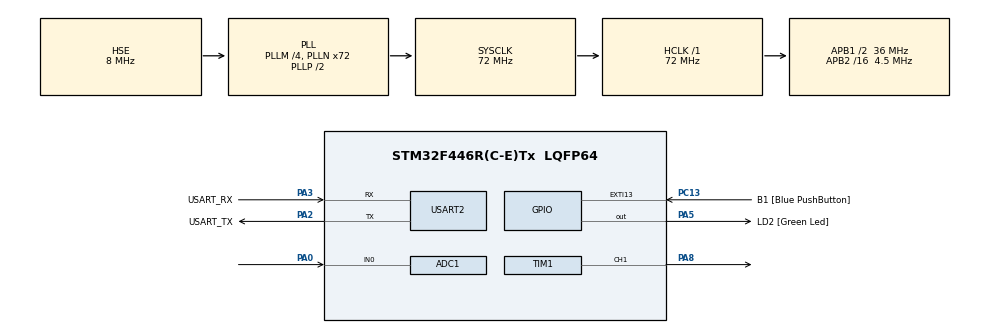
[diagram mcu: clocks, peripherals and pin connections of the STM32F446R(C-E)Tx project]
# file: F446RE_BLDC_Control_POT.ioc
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ADC1.Channel-0\#ChannelRegularConversion=ADC_CHANNEL_0
ADC1.ContinuousConvMode=ENABLE
ADC1.NbrOfConversionFlag=1
ADC1.Rank-0\#ChannelRegularConversion=1
ADC1.SamplingTime-0\#ChannelRegularConversion=ADC_SAMPLETIME_3CYCLES
ADC1.ScanConvMode=ENABLE
ADC1.master=1
Dma.ADC1.0.Direction=DMA_PERIPH_TO_MEMORY
Dma.ADC1.0.FIFOMode=DMA_FIFOMODE_DISABLE
Dma.ADC1.0.Instance=DMA2_Stream0
Dma.ADC1.0.MemDataAlignment=DMA_MDATAALIGN_HALFWORD
Dma.ADC1.0.MemInc=DMA_MINC_ENABLE
Dma.ADC1.0.Mode=DMA_CIRCULAR
Dma.ADC1.0.PeriphDataAlignment=DMA_PDATAALIGN_HALFWORD
Dma.ADC1.0.PeriphInc=DMA_PINC_DISABLE
Dma.ADC1.0.Priority=DMA_PRIORITY_LOW
Dma.Request0=ADC1
Mcu.Family=STM32F4
Mcu.Name=STM32F446R(C-E)Tx
Mcu.Package=LQFP64
NVIC.ADC_IRQn=true\:0\:0\:false\:false\:true\:true\:true\:true
NVIC.DMA2_Stream0_IRQn=true\:0\:0\:false\:false\:true\:false\:true\:true
NVIC.PriorityGroup=NVIC_PRIORITYGROUP_0
PA0-WKUP.Signal=ADCx_IN0
PA13.GPIO_Label=TMS
PA13.Mode=Serial_Wire
PA13.Signal=SYS_JTMS-SWDIO
PA14.GPIO_Label=TCK
PA14.Mode=Serial_Wire
PA14.Signal=SYS_JTCK-SWCLK
PA2.GPIO_Label=USART_TX
PA2.Mode=Asynchronous
PA2.Signal=USART2_TX
PA3.GPIO_Label=USART_RX
PA3.Mode=Asynchronous
PA3.Signal=USART2_RX
PA5.GPIO_Label=LD2 [Green Led]
PA5.Signal=GPIO_Output
PA8.Signal=S_TIM1_CH1
PB3.GPIO_Label=SWO
PB3.Signal=SYS_JTDO-SWO
PC13.GPIO_Label=B1 [Blue PushButton]
PC13.GPIO_ModeDefaultEXTI=GPIO_MODE_IT_FALLING
PC13.Signal=GPXTI13
PC14-OSC32_IN.Mode=LSE-External-Oscillator
PC14-OSC32_IN.Signal=RCC_OSC32_IN
PC15-OSC32_OUT.Mode=LSE-External-Oscillator
PC15-OSC32_OUT.Signal=RCC_OSC32_OUT
PH0-OSC_IN.Mode=HSE-External-Oscillator
PH0-OSC_IN.Signal=RCC_OSC_IN
PH1-OSC_OUT.Mode=HSE-External-Oscillator
PH1-OSC_OUT.Signal=RCC_OSC_OUT
ProjectManager.HeapSize=0x200
ProjectManager.StackSize=0x400
ProjectManager.TargetToolchain=STM32CubeIDE
RCC.48MHZClocksFreq_Value=84000000
RCC.AHBFreq_Value=72000000
RCC.APB1CLKDivider=RCC_HCLK_DIV2
RCC.APB1Freq_Value=36000000
RCC.APB1TimFreq_Value=72000000
RCC.APB2CLKDivider=RCC_HCLK_DIV16
RCC.APB2Freq_Value=4500000
RCC.APB2TimFreq_Value=9000000
RCC.CortexFreq_Value=72000000
RCC.FLatency-AdvancedSettings=FLASH_LATENCY_2
RCC.HCLKFreq_Value=72000000
RCC.HSE_VALUE=8000000
RCC.HSI_VALUE=16000000
RCC.PLLM=4
RCC.PLLN=72
RCC.PLLSourceVirtual=RCC_PLLSOURCE_HSE
RCC.SYSCLKFreq_VALUE=72000000
RCC.SYSCLKSource=RCC_SYSCLKSOURCE_PLLCLK
RCC.USBFreq_Value=72000000
RCC.VCOOutputFreq_Value=144000000
SH.ADCx_IN0.0=ADC1_IN0,IN0
SH.S_TIM1_CH1.0=TIM1_CH1,PWM Generation1 CH1
TIM1.Channel-PWM\ Generation1\ CH1=TIM_CHANNEL_1
TIM1.Period=1000-1
TIM1.Prescaler=180-1
USART2.VirtualMode=VM_ASYNC
VP_TIM1_VS_ClockSourceINT.Mode=Internal
board=NUCLEO-F446RE

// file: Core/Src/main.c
/* USER CODE BEGIN Header */
/**
  ******************************************************************************
  * @file           : main.c
  * @brief          : Main program body
  ******************************************************************************
  * @attention
  *
  * Copyright (c) 2024 STMicroelectronics.
  * All rights reserved.
  *
  * This software is licensed under terms that can be found in the LICENSE file
  * in the root directory of this software component.
  * If no LICENSE file comes with this software, it is provided AS-IS.
  *
  ******************************************************************************
  */
/* USER CODE END Header */
#include "main.h"

ADC_HandleTypeDef hadc1;
DMA_HandleTypeDef hdma_adc1;

TIM_HandleTypeDef htim1;

UART_HandleTypeDef huart2;

void SystemClock_Config(void);
static void MX_GPIO_Init(void);
static void MX_DMA_Init(void);
static void MX_USART2_UART_Init(void);
static void MX_TIM1_Init(void);
static void MX_ADC1_Init(void);

/* USER CODE BEGIN 0 */
uint16_t i = 0;
uint16_t adc_value = 0;
uint16_t ADc_Converted = 0;

long map(long x, long in_min, long in_max, long out_min, long out_max) {
  return (x - in_min) * (out_max - out_min) / (in_max - in_min) + out_min;
}

void HAL_ADC_ConvCpltCallback(ADC_HandleTypeDef* hadc)
{

}
/* USER CODE END 0 */

int main(void)
{

  /* MCU Configuration--------------------------------------------------------*/

  /* Reset of all peripherals, Initializes the Flash interface and the Systick. */
  HAL_Init();

  /* Configure the system clock */
  SystemClock_Config();

  /* Initialize all configured peripherals */
  MX_GPIO_Init();
  MX_DMA_Init();
  MX_USART2_UART_Init();
  MX_TIM1_Init();
  MX_ADC1_Init();
  /* USER CODE BEGIN 2 */
  HAL_TIM_PWM_Start(&htim1, TIM_CHANNEL_1);

  HAL_ADC_Start_DMA(&hadc1, (uint32_t *)&adc_value, 1);

  /* USER CODE END 2 */

  /* Infinite loop */
  while (1)
  {

  }
}

void SystemClock_Config(void)
{
  RCC_OscInitTypeDef RCC_OscInitStruct = {0};
  RCC_ClkInitTypeDef RCC_ClkInitStruct = {0};

  /** Configure the main internal regulator output voltage
  */
  __HAL_RCC_PWR_CLK_ENABLE();
  __HAL_PWR_VOLTAGESCALING_CONFIG(PWR_REGULATOR_VOLTAGE_SCALE3);

  /** Initializes the RCC Oscillators according to the specified parameters
  * in the RCC_OscInitTypeDef structure.
  */
  RCC_OscInitStruct.OscillatorType = RCC_OSCILLATORTYPE_HSE;
  RCC_OscInitStruct.HSEState = RCC_HSE_ON;
  RCC_OscInitStruct.PLL.PLLState = RCC_PLL_ON;
  RCC_OscInitStruct.PLL.PLLSource = RCC_PLLSOURCE_HSE;
  RCC_OscInitStruct.PLL.PLLM = 4;
  RCC_OscInitStruct.PLL.PLLN = 72;
  RCC_OscInitStruct.PLL.PLLP = RCC_PLLP_DIV2;
  RCC_OscInitStruct.PLL.PLLQ = 2;
  RCC_OscInitStruct.PLL.PLLR = 2;
  if (HAL_RCC_OscConfig(&RCC_OscInitStruct) != HAL_OK)
  {
    Error_Handler();
  }

  /** Initializes the CPU, AHB and APB buses clocks
  */
  RCC_ClkInitStruct.ClockType = RCC_CLOCKTYPE_HCLK|RCC_CLOCKTYPE_SYSCLK
                              |RCC_CLOCKTYPE_PCLK1|RCC_CLOCKTYPE_PCLK2;
  RCC_ClkInitStruct.SYSCLKSource = RCC_SYSCLKSOURCE_PLLCLK;
  RCC_ClkInitStruct.AHBCLKDivider = RCC_SYSCLK_DIV1;
  RCC_ClkInitStruct.APB1CLKDivider = RCC_HCLK_DIV2;
  RCC_ClkInitStruct.APB2CLKDivider = RCC_HCLK_DIV16;

  if (HAL_RCC_ClockConfig(&RCC_ClkInitStruct, FLASH_LATENCY_2) != HAL_OK)
  {
    Error_Handler();
  }
}

static void MX_ADC1_Init(void)
{

  ADC_ChannelConfTypeDef sConfig = {0};

  /** Configure the global features of the ADC (Clock, Resolution, Data Alignment and number of conversion)
  */
  hadc1.Instance = ADC1;
  hadc1.Init.ClockPrescaler = ADC_CLOCK_SYNC_PCLK_DIV2;
  hadc1.Init.Resolution = ADC_RESOLUTION_12B;
  hadc1.Init.ScanConvMode = ENABLE;
  hadc1.Init.ContinuousConvMode = ENABLE;
  hadc1.Init.DiscontinuousConvMode = DISABLE;
  hadc1.Init.ExternalTrigConvEdge = ADC_EXTERNALTRIGCONVEDGE_NONE;
  hadc1.Init.ExternalTrigConv = ADC_SOFTWARE_START;
  hadc1.Init.DataAlign = ADC_DATAALIGN_RIGHT;
  hadc1.Init.NbrOfConversion = 1;
  hadc1.Init.DMAContinuousRequests = DISABLE;
  hadc1.Init.EOCSelection = ADC_EOC_SINGLE_CONV;
  if (HAL_ADC_Init(&hadc1) != HAL_OK)
  {
    Error_Handler();
  }

  /** Configure for the selected ADC regular channel its corresponding rank in the sequencer and its sample time.
  */
  sConfig.Channel = ADC_CHANNEL_0;
  sConfig.Rank = 1;
  sConfig.SamplingTime = ADC_SAMPLETIME_3CYCLES;
  if (HAL_ADC_ConfigChannel(&hadc1, &sConfig) != HAL_OK)
  {
    Error_Handler();
  }

}

static void MX_TIM1_Init(void)
{

  TIM_ClockConfigTypeDef sClockSourceConfig = {0};
  TIM_MasterConfigTypeDef sMasterConfig = {0};
  TIM_OC_InitTypeDef sConfigOC = {0};
  TIM_BreakDeadTimeConfigTypeDef sBreakDeadTimeConfig = {0};

  htim1.Instance = TIM1;
  htim1.Init.Prescaler = 180-1;
  htim1.Init.CounterMode = TIM_COUNTERMODE_UP;
  htim1.Init.Period = 1000-1;
  htim1.Init.ClockDivision = TIM_CLOCKDIVISION_DIV1;
  htim1.Init.RepetitionCounter = 0;
  htim1.Init.AutoReloadPreload = TIM_AUTORELOAD_PRELOAD_DISABLE;
  if (HAL_TIM_Base_Init(&htim1) != HAL_OK)
  {
    Error_Handler();
  }
  sClockSourceConfig.ClockSource = TIM_CLOCKSOURCE_INTERNAL;
  if (HAL_TIM_ConfigClockSource(&htim1, &sClockSourceConfig) != HAL_OK)
  {
    Error_Handler();
  }
  if (HAL_TIM_PWM_Init(&htim1) != HAL_OK)
  {
    Error_Handler();
  }
  sMasterConfig.MasterOutputTrigger = TIM_TRGO_RESET;
  sMasterConfig.MasterSlaveMode = TIM_MASTERSLAVEMODE_DISABLE;
  if (HAL_TIMEx_MasterConfigSynchronization(&htim1, &sMasterConfig) != HAL_OK)
  {
    Error_Handler();
  }
  sConfigOC.OCMode = TIM_OCMODE_PWM1;
  sConfigOC.Pulse = 0;
  sConfigOC.OCPolarity = TIM_OCPOLARITY_HIGH;
  sConfigOC.OCNPolarity = TIM_OCNPOLARITY_HIGH;
  sConfigOC.OCFastMode = TIM_OCFAST_DISABLE;
  sConfigOC.OCIdleState = TIM_OCIDLESTATE_RESET;
  sConfigOC.OCNIdleState = TIM_OCNIDLESTATE_RESET;
  if (HAL_TIM_PWM_ConfigChannel(&htim1, &sConfigOC, TIM_CHANNEL_1) != HAL_OK)
  {
    Error_Handler();
  }
  sBreakDeadTimeConfig.OffStateRunMode = TIM_OSSR_DISABLE;
  sBreakDeadTimeConfig.OffStateIDLEMode = TIM_OSSI_DISABLE;
  sBreakDeadTimeConfig.LockLevel = TIM_LOCKLEVEL_OFF;
  sBreakDeadTimeConfig.DeadTime = 0;
  sBreakDeadTimeConfig.BreakState = TIM_BREAK_DISABLE;
  sBreakDeadTimeConfig.BreakPolarity = TIM_BREAKPOLARITY_HIGH;
  sBreakDeadTimeConfig.AutomaticOutput = TIM_AUTOMATICOUTPUT_DISABLE;
  if (HAL_TIMEx_ConfigBreakDeadTime(&htim1, &sBreakDeadTimeConfig) != HAL_OK)
  {
    Error_Handler();
  }
  HAL_TIM_MspPostInit(&htim1);

}

static void MX_USART2_UART_Init(void)
{

  huart2.Instance = USART2;
  huart2.Init.BaudRate = 115200;
  huart2.Init.WordLength = UART_WORDLENGTH_8B;
  huart2.Init.StopBits = UART_STOPBITS_1;
  huart2.Init.Parity = UART_PARITY_NONE;
  huart2.Init.Mode = UART_MODE_TX_RX;
  huart2.Init.HwFlowCtl = UART_HWCONTROL_NONE;
  huart2.Init.OverSampling = UART_OVERSAMPLING_16;
  if (HAL_UART_Init(&huart2) != HAL_OK)
  {
    Error_Handler();
  }

}

static void MX_DMA_Init(void)
{

  /* DMA controller clock enable */
  __HAL_RCC_DMA2_CLK_ENABLE();

  /* DMA interrupt init */
  /* DMA2_Stream0_IRQn interrupt configuration */
  HAL_NVIC_SetPriority(DMA2_Stream0_IRQn, 0, 0);
  HAL_NVIC_EnableIRQ(DMA2_Stream0_IRQn);

}

static void MX_GPIO_Init(void)
{
  GPIO_InitTypeDef GPIO_InitStruct = {0};

  /* GPIO Ports Clock Enable */
  __HAL_RCC_GPIOC_CLK_ENABLE();
  __HAL_RCC_GPIOH_CLK_ENABLE();
  __HAL_RCC_GPIOA_CLK_ENABLE();
  __HAL_RCC_GPIOB_CLK_ENABLE();

  /*Configure GPIO pin Output Level */
  HAL_GPIO_WritePin(LD2_GPIO_Port, LD2_Pin, GPIO_PIN_RESET);

  /*Configure GPIO pin : B1_Pin */
  GPIO_InitStruct.Pin = B1_Pin;
  GPIO_InitStruct.Mode = GPIO_MODE_IT_FALLING;
  GPIO_InitStruct.Pull = GPIO_NOPULL;
  HAL_GPIO_Init(B1_GPIO_Port, &GPIO_InitStruct);

  /*Configure GPIO pin : LD2_Pin */
  GPIO_InitStruct.Pin = LD2_Pin;
  GPIO_InitStruct.Mode = GPIO_MODE_OUTPUT_PP;
  GPIO_InitStruct.Pull = GPIO_NOPULL;
  GPIO_InitStruct.Speed = GPIO_SPEED_FREQ_LOW;
  HAL_GPIO_Init(LD2_GPIO_Port, &GPIO_InitStruct);

}

void Error_Handler(void)
{
  __disable_irq();
  while (1)
  {
  }
}
